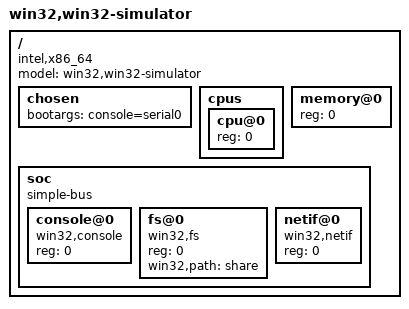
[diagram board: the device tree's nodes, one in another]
/dts-v1/;

/ {
    model = "win32,win32-simulator";
    compatible = "intel,x86_64";
	#address-cells = <1>;
	#size-cells = <0>;

	chosen {
		bootargs = "console=serial0";
	};

    cpus {
		#address-cells = <1>;
		#size-cells = <0>;

	    cpu@0 {
	        device_type = "cpu";
			reg = <0>;
	    };
	};

	memory@0 {
		device_type = "memory";
		reg = <0>;
	};
	
	soc {
		#address-cells = <1>;
		#size-cells = <0>;

		compatible = "simple-bus";
		ranges = <0 0>;

		console@0 {
			compatible = "win32,console";
			reg = <0>;
		};

		fs@0 {
			compatible = "win32,fs";
			reg = <0>;
			win32,path = "share";
		};

		netif@0 {
			compatible = "win32,netif";
			reg = <0>;
		};
	};
};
